VERSION ""

NS_ :

BS_:

BU_: IVS UDS BRK STR ENG BMS

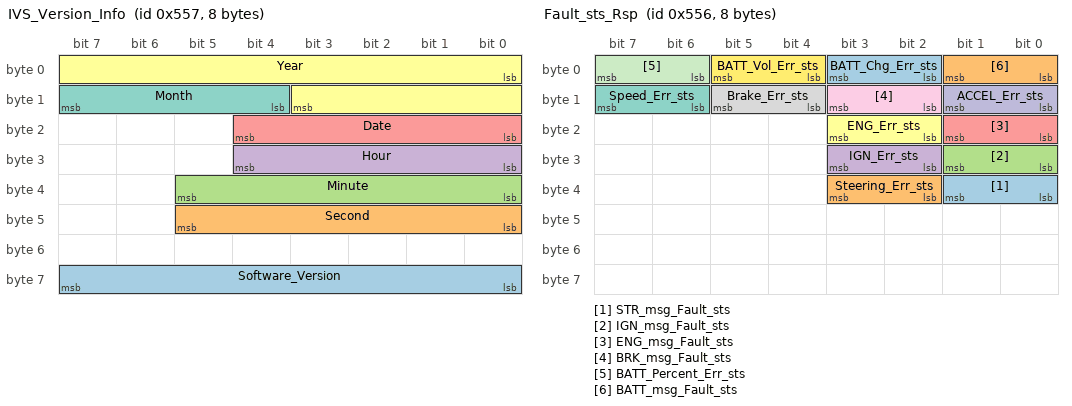
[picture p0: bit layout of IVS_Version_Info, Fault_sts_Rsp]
BO_ 1367 IVS_Version_Info: 8 IVS
 SG_ Software_Version : 56|8@1+ (1,0) [0|0] "NA" Vector__XXX
 SG_ Second : 40|6@1+ (1,0) [0|0] "NA" Vector__XXX
 SG_ Minute : 32|6@1+ (1,0) [0|0] "NA" Vector__XXX
 SG_ Hour : 24|5@1+ (1,0) [0|0] "NA" Vector__XXX
 SG_ Date : 16|5@1+ (1,0) [0|0] "NA" Vector__XXX
 SG_ Year : 0|12@1+ (1,0) [0|0] "NA" Vector__XXX
 SG_ Month : 12|4@1+ (1,0) [1|12] "NA" Vector__XXX

BO_ 1366 Fault_sts_Rsp: 8 IVS
 SG_ STR_msg_Fault_sts : 32|2@1+ (1,0) [0|0] "NA" Vector__XXX
 SG_ Steering_Err_sts : 34|2@1+ (1,0) [0|0] "NA" Vector__XXX
 SG_ IGN_msg_Fault_sts : 24|2@1+ (1,0) [0|0] "NA" Vector__XXX
 SG_ IGN_Err_sts : 26|2@1+ (1,0) [0|0] "NA" Vector__XXX
 SG_ ENG_msg_Fault_sts : 16|2@1+ (1,0) [0|0] "NA" Vector__XXX
 SG_ ENG_Err_sts : 18|2@1+ (1,0) [0|0] "NA" Vector__XXX
 SG_ Speed_Err_sts : 14|2@1+ (1,0) [0|0] "NA" Vector__XXX
 SG_ Brake_Err_sts : 12|2@1+ (1,0) [0|0] "NA" Vector__XXX
 SG_ BRK_msg_Fault_sts : 10|2@1+ (1,0) [0|0] "NA" Vector__XXX
 SG_ ACCEL_Err_sts : 8|2@1+ (1,0) [0|0] "NA" Vector__XXX
 SG_ BATT_Percent_Err_sts : 6|2@1+ (1,0) [0|0] "NA" Vector__XXX
 SG_ BATT_Vol_Err_sts : 4|2@1+ (1,0) [0|0] "NA" Vector__XXX
 SG_ BATT_Chg_Err_sts : 2|2@1+ (1,0) [0|0] "NA" Vector__XXX
 SG_ BATT_msg_Fault_sts : 0|2@1+ (1,0) [0|0] "NA" Vector__XXX

BO_ 1365 Fault_sts_Req: 8 UDS
 SG_ All_Fault_sts_request : 0|1@1+ (1,0) [0|1] "NA" Vector__XXX
 SG_ All_Fault_clr_request : 8|1@1+ (1,0) [0|1] "NA" Vector__XXX

BO_ 1364 IVS_Version_Req: 8 UDS
 SG_ Software_Version_Request : 0|1@1+ (1,0) [0|1] "NA" Vector__XXX

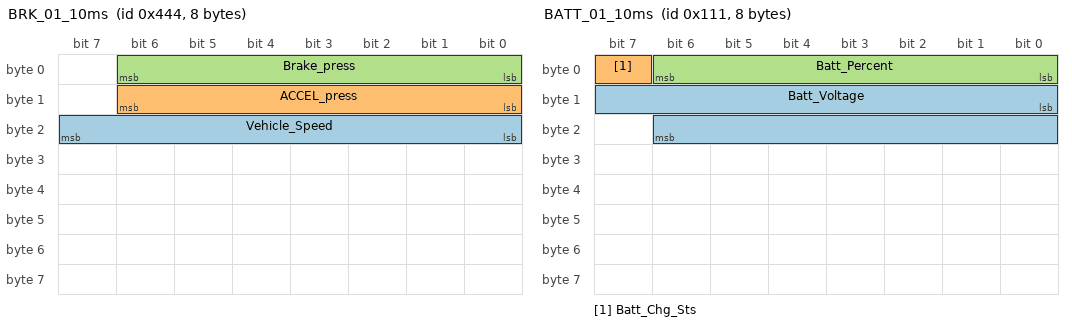
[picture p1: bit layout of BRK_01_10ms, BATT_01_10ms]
BO_ 1092 BRK_01_10ms: 8 BRK
 SG_ Vehicle_Speed : 16|8@1+ (1,0) [0|254] "km/h" Vector__XXX
 SG_ ACCEL_press : 8|7@1+ (1,0) [0|100] "%" Vector__XXX
 SG_ Brake_press : 0|7@1+ (1,0) [0|100] "%" Vector__XXX

BO_ 819 STR_01_10ms: 8 STR
 SG_ Steering_angle : 0|12@1- (1,0) [-720|720] "degree" Vector__XXX

BO_ 547 ENG_02_10ms: 8 ENG
 SG_ Engine_sts : 0|2@1+ (1,0) [0|2] "NA"  ENG

BO_ 546 IGN_01_2ms: 8 ENG
 SG_ Ignition_sts : 0|2@1+ (1,0) [0|3] "NA"  ENG

BO_ 273 BATT_01_10ms: 8 BMS
 SG_ Batt_Voltage : 8|15@1+ (0.001,0) [0|20] "V" Vector__XXX
 SG_ Batt_Chg_Sts : 7|1@1+ (1,0) [0|1] "NA" Vector__XXX
 SG_ Batt_Percent : 0|7@1+ (1,0) [0|100] "%" Vector__XXX
